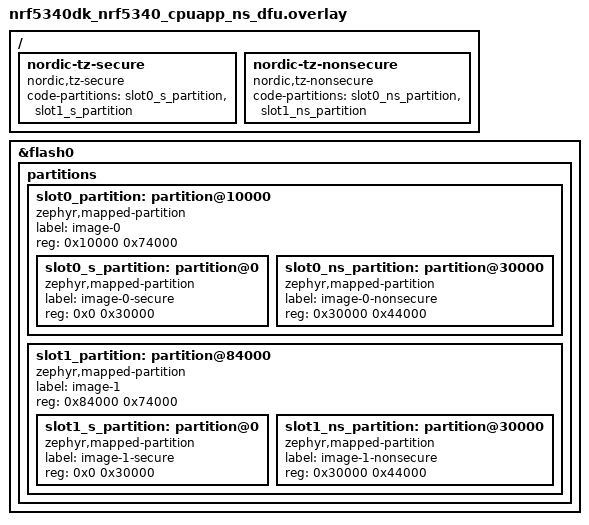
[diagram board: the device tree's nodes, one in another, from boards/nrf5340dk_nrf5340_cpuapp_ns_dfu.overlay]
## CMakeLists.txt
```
#
# Copyright (c) 2019 Nordic Semiconductor ASA
#
# SPDX-License-Identifier: LicenseRef-Nordic-5-Clause
#
cmake_minimum_required(VERSION 3.20.0)

find_package(Zephyr REQUIRED HINTS $ENV{ZEPHYR_BASE})
project(bluetooth_mesh_light)

include_directories(${ZEPHYR_NRF_MODULE_DIR}/samples/bluetooth/mesh/common)

# NORDIC SDK APP START
target_sources(app PRIVATE
  src/main.c
  src/model_handler.c
)
target_include_directories(app PRIVATE
  include
  ${ZEPHYR_NRF_MODULE_DIR}/samples/bluetooth/mesh/common
)

# Preinitialization related to DFU over SMP
target_sources_ifdef(CONFIG_MCUMGR_TRANSPORT_BT app PRIVATE
  ${ZEPHYR_NRF_MODULE_DIR}/samples/bluetooth/mesh/common/smp_bt.c
  ${ZEPHYR_NRF_MODULE_DIR}/samples/bluetooth/mesh/common/mgmt_dfu_hooks.c
)

# NORDIC SDK APP END
```

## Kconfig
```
source "Kconfig.zephyr"

rsource "../common/Kconfig"
```

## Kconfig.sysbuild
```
#
# Copyright (c) 2023 Nordic Semiconductor
#
# SPDX-License-Identifier: LicenseRef-Nordic-5-Clause
#

config NRF_DEFAULT_IPC_RADIO
	default y

config PARTITION_MANAGER
	default n if !BOARD_NRF5340DK_NRF5340_CPUAPP_NS && !BOOTLOADER_MCUBOOT && !BOARD_THINGY53_NRF5340_CPUAPP

source "share/sysbuild/Kconfig"
```

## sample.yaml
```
sample:
  description: Bluetooth Mesh light sample
  name: Bluetooth Mesh light
common:
  tags:
    - bluetooth
    - ci_build
    - sysbuild
    - ci_samples_bluetooth
tests:
  sample.bluetooth.mesh.light:
    sysbuild: true
    build_only: true
    integration_platforms:
      - nrf54l15dk/nrf54l15/cpuapp
    platform_allow:
      - nrf5340dk/nrf5340/cpuapp
      - nrf5340dk/nrf5340/cpuapp/ns
      - nrf54l15dk/nrf54l15/cpuapp
      - nrf54l15dk/nrf54l10/cpuapp
      - nrf54l15dk/nrf54l05/cpuapp
      - nrf54lm20dk/nrf54lm20a/cpuapp
      - nrf54lm20dk/nrf54lm20a/cpuapp/ite
      - nrf54lc10dk/nrf54lc10a/cpuapp
  sample.bluetooth.mesh.light.dfu:
    sysbuild: true
    build_only: true
    integration_platforms:
      - nrf54l15dk/nrf54l15/cpuapp
    platform_allow:
      - nrf5340dk/nrf5340/cpuapp
      - nrf5340dk/nrf5340/cpuapp/ns
      - nrf54l15dk/nrf54l15/cpuapp
      - nrf54l15dk/nrf54l10/cpuapp
      - nrf54lm20dk/nrf54lm20a/cpuapp
      - nrf54lc10dk/nrf54lc10a/cpuapp
    extra_args: FILE_SUFFIX=dfu
  sample.bluetooth.mesh.light.settings_ext_flash:
    sysbuild: true
    build_only: true
    integration_platforms:
      - nrf54l15dk/nrf54l15/cpuapp
    platform_allow:
      - nrf54l15dk/nrf54l15/cpuapp
      - nrf54l15dk/nrf54l10/cpuapp
      - nrf54l15dk/nrf54l05/cpuapp
    extra_args: FILE_SUFFIX=settings_ext_flash
```

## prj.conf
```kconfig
#
# Copyright (c) 2019 Nordic Semiconductor ASA
#
# SPDX-License-Identifier: LicenseRef-Nordic-5-Clause
#
CONFIG_NCS_SAMPLES_DEFAULTS=y

# Deferred logging helps improve LPN power consumption
# when friendship is established.
CONFIG_LOG_MODE_DEFERRED=y

# General configuration
CONFIG_NCS_APPLICATION_BOOT_BANNER_STRING="Mesh Light"
CONFIG_SYSTEM_WORKQUEUE_STACK_SIZE=3072
CONFIG_FLASH=y
CONFIG_FLASH_MAP=y
CONFIG_NVS=y
CONFIG_SETTINGS=y
CONFIG_NVS_LOOKUP_CACHE=y
CONFIG_SETTINGS_NVS_NAME_CACHE=y
CONFIG_HWINFO=y
CONFIG_DK_LIBRARY=y
CONFIG_SOC_FLASH_NRF_PARTIAL_ERASE=y
CONFIG_BT_MESH_NODE_RESET_BUTTON=y

# Bluetooth configuration
CONFIG_BT=y
CONFIG_BT_DEVICE_NAME="Mesh Light"
CONFIG_BT_L2CAP_TX_BUF_COUNT=8

CONFIG_BT_OBSERVER=y
CONFIG_BT_PERIPHERAL=y
CONFIG_BT_SETTINGS=y
# Increase RX stack size to avoid overflow during provisioning
CONFIG_BT_RX_STACK_SIZE=2700

# Disable unused Bluetooth features
CONFIG_BT_CTLR_LE_ENC=n
CONFIG_BT_PHY_UPDATE=n
CONFIG_BT_CTLR_CHAN_SEL_2=n
CONFIG_BT_CTLR_MIN_USED_CHAN=n
CONFIG_BT_CTLR_PRIVACY=n

# Bluetooth Mesh configuration
CONFIG_BT_MESH=y
CONFIG_BT_MESH_RELAY=y
CONFIG_BT_MESH_FRIEND=y
CONFIG_BT_MESH_TX_SEG_MAX=10
CONFIG_BT_MESH_PB_GATT=y
CONFIG_BT_MESH_GATT_PROXY=y
CONFIG_BT_MESH_PROXY_USE_DEVICE_NAME=y
CONFIG_BT_MESH_DK_PROV=y

# Bluetooth Mesh models
CONFIG_BT_MESH_ONOFF_SRV=y

CONFIG_LTO=y
CONFIG_ISR_TABLES_LOCAL_DECLARATION=y
```

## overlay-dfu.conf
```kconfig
#
# Copyright (c) 2022 Nordic Semiconductor ASA
#
# SPDX-License-Identifier: LicenseRef-Nordic-5-Clause
#

# Enable point to point DFU over SMP
CONFIG_BOOTLOADER_MCUBOOT=y
CONFIG_NCS_SAMPLE_MCUMGR_BT_OTA_DFU=y
CONFIG_NCS_SAMPLE_MCUMGR_BT_OTA_DFU_SPEEDUP=y
CONFIG_MCUMGR_TRANSPORT_WORKQUEUE_STACK_SIZE=3072
# Enable Extended Advertiser to advertise BT SMP service
CONFIG_BT_EXT_ADV=y
CONFIG_BT_EXT_ADV_MAX_ADV_SET=6

# One extra connection for mesh GATT/proxy and one for SMP BT.
CONFIG_BT_MAX_CONN=3

# One extra identity for SMP service
CONFIG_BT_ID_MAX=2

# Increase the HCI command buffers to 3 for additional SMP service
CONFIG_BT_BUF_CMD_TX_COUNT=3

# Enable MCUmgr command hooks for doing mesh reset when doing dfu upgrade and storage erase
CONFIG_MCUMGR_MGMT_NOTIFICATION_HOOKS=y
CONFIG_MCUMGR_SMP_COMMAND_STATUS_HOOKS=y
CONFIG_MCUMGR_GRP_OS_RESET_HOOK=y

# Force disconnect after PB-GATT provisioning for proper Proxy transition after DFU
CONFIG_BT_MESH_DK_PROV_PB_GATT_DISCONNECT=y
```

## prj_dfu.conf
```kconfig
#
# Copyright (c) 2026 Nordic Semiconductor ASA
#
# SPDX-License-Identifier: LicenseRef-Nordic-5-Clause
#
CONFIG_NCS_SAMPLES_DEFAULTS=y

# Deferred logging helps improve LPN power consumption
# when friendship is established.
CONFIG_LOG_MODE_DEFERRED=y

# General configuration
CONFIG_NCS_APPLICATION_BOOT_BANNER_STRING="Mesh Light"
CONFIG_SYSTEM_WORKQUEUE_STACK_SIZE=3072
CONFIG_FLASH=y
CONFIG_FLASH_MAP=y
CONFIG_NVS=y
CONFIG_SETTINGS=y
CONFIG_NVS_LOOKUP_CACHE=y
CONFIG_SETTINGS_NVS_NAME_CACHE=y
CONFIG_HWINFO=y
CONFIG_DK_LIBRARY=y
CONFIG_SOC_FLASH_NRF_PARTIAL_ERASE=y

# Bluetooth configuration
CONFIG_BT=y
CONFIG_BT_DEVICE_NAME="Mesh Light"
CONFIG_BT_L2CAP_TX_BUF_COUNT=8

CONFIG_BT_OBSERVER=y
CONFIG_BT_PERIPHERAL=y
CONFIG_BT_SETTINGS=y
# Increase RX stack size to avoid overflow during provisioning
CONFIG_BT_RX_STACK_SIZE=2700

# Disable unused Bluetooth features
CONFIG_BT_CTLR_LE_ENC=n
CONFIG_BT_PHY_UPDATE=n
CONFIG_BT_CTLR_CHAN_SEL_2=n
CONFIG_BT_CTLR_MIN_USED_CHAN=n
CONFIG_BT_CTLR_PRIVACY=n

# Bluetooth Mesh configuration
CONFIG_BT_MESH=y
CONFIG_BT_MESH_RELAY=y
CONFIG_BT_MESH_FRIEND=y
CONFIG_BT_MESH_TX_SEG_MAX=10
CONFIG_BT_MESH_PB_GATT=y
CONFIG_BT_MESH_GATT_PROXY=y
CONFIG_BT_MESH_PROXY_USE_DEVICE_NAME=y
CONFIG_BT_MESH_DK_PROV=y

# Bluetooth Mesh models
CONFIG_BT_MESH_ONOFF_SRV=y

# === BLE DFU configuration ===
# Enable point to point DFU over SMP
CONFIG_BOOTLOADER_MCUBOOT=y
CONFIG_NCS_SAMPLE_MCUMGR_BT_OTA_DFU=y
CONFIG_NCS_SAMPLE_MCUMGR_BT_OTA_DFU_SPEEDUP=y
CONFIG_MCUMGR_TRANSPORT_WORKQUEUE_STACK_SIZE=3072
# Enable Extended Advertiser to advertise BT SMP service
CONFIG_BT_EXT_ADV=y
CONFIG_BT_EXT_ADV_MAX_ADV_SET=6

# One extra connection for mesh GATT/proxy and one for SMP BT.
CONFIG_BT_MAX_CONN=3

# One extra identity for SMP service
CONFIG_BT_ID_MAX=2

# Increase the HCI command buffers to 3 for additional SMP service
CONFIG_BT_BUF_CMD_TX_COUNT=3

# Enable MCUmgr command hooks for doing mesh reset when doing dfu upgrade and storage erase
CONFIG_MCUMGR_MGMT_NOTIFICATION_HOOKS=y
CONFIG_MCUMGR_SMP_COMMAND_STATUS_HOOKS=y
CONFIG_MCUMGR_GRP_OS_RESET_HOOK=y

# Force disconnect after PB-GATT provisioning for proper Proxy transition after DFU
CONFIG_BT_MESH_DK_PROV_PB_GATT_DISCONNECT=y

# Link Time Optimization. CONFIG_LTO depends on ISR_TABLES_LOCAL_DECLARATION
CONFIG_LTO=y
CONFIG_ISR_TABLES_LOCAL_DECLARATION=y
```

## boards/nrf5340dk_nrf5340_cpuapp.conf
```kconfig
#
# Copyright (c) 2024 Nordic Semiconductor ASA
#
# SPDX-License-Identifier: LicenseRef-Nordic-5-Clause
#
################################################################################
# Application overlay - nrf5340dk secure image

CONFIG_SOC_FLASH_NRF_PARTIAL_ERASE=n

# Enable point to point DFU over SMP
CONFIG_BOOTLOADER_MCUBOOT=y
CONFIG_NCS_SAMPLE_MCUMGR_BT_OTA_DFU=y
CONFIG_NCS_SAMPLE_MCUMGR_BT_OTA_DFU_SPEEDUP=y

# Enable updates for the network core
CONFIG_NRF53_UPGRADE_NETWORK_CORE=y
CONFIG_UPDATEABLE_IMAGE_NUMBER=2
CONFIG_MCUBOOT_USE_ALL_AVAILABLE_RAM=y

# Enable Extended Advertiser to advertise BT SMP service
CONFIG_BT_EXT_ADV=y
CONFIG_BT_EXT_ADV_MAX_ADV_SET=6

# One extra connection for mesh GATT/proxy and one for SMP BT.
CONFIG_BT_MAX_CONN=3

# One extra identity for SMP service
CONFIG_BT_ID_MAX=2
```

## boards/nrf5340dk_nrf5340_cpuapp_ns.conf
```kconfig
#
# Copyright (c) 2023 Nordic Semiconductor ASA
#
# SPDX-License-Identifier: LicenseRef-Nordic-5-Clause
#
################################################################################
# Application overlay - nrf5340dk non secure image

CONFIG_SOC_FLASH_NRF_PARTIAL_ERASE=n

# Use the TF-M Profile Small to save ROM and be able to fit when using bootloader
CONFIG_TFM_PROFILE_TYPE_SMALL=y
```

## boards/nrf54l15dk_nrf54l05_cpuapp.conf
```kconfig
#
# Copyright (c) 2024 Nordic Semiconductor ASA
#
# SPDX-License-Identifier: LicenseRef-Nordic-5-Clause
#
################################################################################
# Application overlay - nrf54l05

CONFIG_SOC_FLASH_NRF_PARTIAL_ERASE=n
CONFIG_SPI_NOR=n
CONFIG_NVS=n
CONFIG_NVS_LOOKUP_CACHE=n
CONFIG_SETTINGS_NVS_NAME_CACHE=n
CONFIG_ZMS=y
CONFIG_SETTINGS_ZMS_CUSTOM_SECTOR_COUNT=y
CONFIG_SETTINGS_ZMS_SECTOR_COUNT=8
CONFIG_ZMS_LOOKUP_CACHE=y
CONFIG_ZMS_LOOKUP_CACHE_SIZE=512
CONFIG_ZMS_LOOKUP_CACHE_FOR_SETTINGS=y
CONFIG_SYSTEM_WORKQUEUE_STACK_SIZE=4096
CONFIG_BT_RX_STACK_SIZE=5120
```

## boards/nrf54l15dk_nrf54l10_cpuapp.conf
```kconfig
#
# Copyright (c) 2024 Nordic Semiconductor ASA
#
# SPDX-License-Identifier: LicenseRef-Nordic-5-Clause
#
################################################################################
# Application overlay - nrf54l10

CONFIG_SOC_FLASH_NRF_PARTIAL_ERASE=n
CONFIG_SPI_NOR=n
CONFIG_NVS=n
CONFIG_NVS_LOOKUP_CACHE=n
CONFIG_SETTINGS_NVS_NAME_CACHE=n
CONFIG_ZMS=y
CONFIG_SETTINGS_ZMS_CUSTOM_SECTOR_COUNT=y
CONFIG_SETTINGS_ZMS_SECTOR_COUNT=8
CONFIG_ZMS_LOOKUP_CACHE=y
CONFIG_ZMS_LOOKUP_CACHE_SIZE=512
CONFIG_ZMS_LOOKUP_CACHE_FOR_SETTINGS=y
CONFIG_SYSTEM_WORKQUEUE_STACK_SIZE=4096
CONFIG_BT_RX_STACK_SIZE=5120
```

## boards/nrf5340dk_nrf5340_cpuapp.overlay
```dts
/*
 * Copyright (c) 2024 Nordic Semiconductor ASA
 *
 * SPDX-License-Identifier: LicenseRef-Nordic-5-Clause
 */

/* Enable external flash */
/ {
	chosen {
		nordic,pm-ext-flash = &mx25r64;
	};
};
```

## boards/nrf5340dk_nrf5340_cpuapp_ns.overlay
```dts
/*
 * Copyright (c) 2026 Nordic Semiconductor ASA
 *
 * SPDX-License-Identifier: LicenseRef-Nordic-5-Clause
 */

/* Rebalance secure/non-secure subpartitions to fit larger mesh light NS image.
 * MCUboot is removed; slot0 starts at 0x0 and spans 928 KB (0xe8000).
 * Secure: 128 KB, Non-secure: 800 KB.
 */

/delete-node/ &boot_partition;
/delete-node/ &slot0_partition;

&flash0 {
	partitions {
		slot0_partition: partition@0 {
			compatible = "zephyr,mapped-partition";
			label = "image-0";
			reg = <0x00000000 0xe8000>;
			ranges = <0x0 0x0 0xe8000>;
			#address-cells = <1>;
			#size-cells = <1>;

			slot0_s_partition: partition@0 {
				compatible = "zephyr,mapped-partition";
				label = "image-0-secure";
				reg = <0x00000000 0x20000>;
			};

			slot0_ns_partition: partition@20000 {
				compatible = "zephyr,mapped-partition";
				label = "image-0-nonsecure";
				reg = <0x00020000 0xc8000>;
			};
		};
	};
};

/ {
	/delete-node/ nordic-tz-secure;
	/delete-node/ nordic-tz-nonsecure;

	nordic-tz-secure {
		compatible = "nordic,tz-secure";
		code-partitions = <&slot0_s_partition>;
	};

	nordic-tz-nonsecure {
		compatible = "nordic,tz-nonsecure";
		code-partitions = <&slot0_ns_partition>;
	};
};
```

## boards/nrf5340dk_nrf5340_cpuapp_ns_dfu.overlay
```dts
/*
 * Copyright (c) 2026 Nordic Semiconductor ASA
 *
 * SPDX-License-Identifier: LicenseRef-Nordic-5-Clause
 */

/* Rebalance secure/non-secure subpartitions to fit larger mesh light NS image.
 * Aligned slot0/slot1 addresses and sizes to MCUboot defaults
 * (nrf5340_cpuapp_partition.dtsi): each slot is 0x74000 (464 KB).
 * Secure: 192 KB, Non-secure: 272 KB.
 */

/delete-node/ &slot0_partition;
/delete-node/ &slot1_partition;

&flash0 {
	partitions {
		slot0_partition: partition@10000 {
			compatible = "zephyr,mapped-partition";
			label = "image-0";
			reg = <0x10000 0x74000>;
			ranges = <0x0 0x10000 0x74000>;
			#address-cells = <1>;
			#size-cells = <1>;

			slot0_s_partition: partition@0 {
				compatible = "zephyr,mapped-partition";
				label = "image-0-secure";
				reg = <0x0 0x30000>;
			};

			slot0_ns_partition: partition@30000 {
				compatible = "zephyr,mapped-partition";
				label = "image-0-nonsecure";
				reg = <0x30000 0x44000>;
			};
		};

		slot1_partition: partition@84000 {
			compatible = "zephyr,mapped-partition";
			label = "image-1";
			reg = <0x84000 0x74000>;
			ranges = <0x0 0x84000 0x74000>;
			#address-cells = <1>;
			#size-cells = <1>;

			slot1_s_partition: partition@0 {
				compatible = "zephyr,mapped-partition";
				label = "image-1-secure";
				reg = <0x0 0x30000>;
			};

			slot1_ns_partition: partition@30000 {
				compatible = "zephyr,mapped-partition";
				label = "image-1-nonsecure";
				reg = <0x30000 0x44000>;
			};
		};
	};
};

/ {
	/delete-node/ nordic-tz-secure;
	/delete-node/ nordic-tz-nonsecure;

	nordic-tz-secure {
		compatible = "nordic,tz-secure";
		code-partitions = <&slot0_s_partition>,
				  <&slot1_s_partition>;
	};

	nordic-tz-nonsecure {
		compatible = "nordic,tz-nonsecure";
		code-partitions = <&slot0_ns_partition>,
				  <&slot1_ns_partition>;
	};
};
```

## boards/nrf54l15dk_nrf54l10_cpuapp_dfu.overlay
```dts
/*
 * Copyright (c) 2026 Nordic Semiconductor ASA
 *
 * SPDX-License-Identifier: LicenseRef-Nordic-5-Clause
 */

/delete-node/ &boot_partition;
/delete-node/ &slot0_partition;
/delete-node/ &slot1_partition;
/delete-node/ &storage_partition;

&cpuapp_rram {
	partitions {
		boot_partition: partition@0 {
			label = "mcuboot";
			reg = <0x0 0xe000>;
		};

		slot0_partition: partition@e000 {
			label = "image-0";
			reg = <0xe000 0x73000>;
		};

		slot1_partition: partition@81000 {
			label = "image-1";
			reg = <0x81000 0x73000>;
		};

		storage_partition: partition@f5000 {
			label = "storage";
			reg = <0xf5000 0x8000>;
		};
	};
};
```

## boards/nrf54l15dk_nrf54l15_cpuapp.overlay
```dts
/*
 * Copyright (c) 2026 Nordic Semiconductor ASA
 *
 * SPDX-License-Identifier: LicenseRef-Nordic-5-Clause
 */

/delete-node/ &boot_partition;
/delete-node/ &slot0_partition;
/delete-node/ &slot1_partition;
/delete-node/ &storage_partition;

&cpuapp_rram {
	partitions {
		boot_partition: partition@0 {
			label = "mcuboot";
			reg = <0x0 0xe000>;
		};

		slot0_partition: partition@e000 {
			label = "image-0";
			reg = <0xe000 0xa7000>;
		};

		slot1_partition: partition@b5000 {
			label = "image-1";
			reg = <0xb5000 0xa7000>;
		};

		storage_partition: partition@15d000 {
			label = "storage";
			reg = <0x15d000 0x8000>;
		};
	};
};
```

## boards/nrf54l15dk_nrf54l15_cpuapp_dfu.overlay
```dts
/*
 * Copyright (c) 2026 Nordic Semiconductor ASA
 *
 * SPDX-License-Identifier: LicenseRef-Nordic-5-Clause
 */

/delete-node/ &boot_partition;
/delete-node/ &slot0_partition;
/delete-node/ &slot1_partition;
/delete-node/ &storage_partition;

&cpuapp_rram {
	partitions {
		boot_partition: partition@0 {
			compatible = "zephyr,mapped-partition";
			label = "mcuboot";
			reg = <0x0 0xe000>;
		};

		slot0_partition: partition@e000 {
			compatible = "zephyr,mapped-partition";
			label = "image-0";
			reg = <0xe000 0xa7000>;
		};

		slot1_partition: partition@b5000 {
			compatible = "zephyr,mapped-partition";
			label = "image-1";
			reg = <0xb5000 0xa7000>;
		};

		storage_partition: partition@15d000 {
			compatible = "zephyr,mapped-partition";
			label = "storage";
			reg = <0x15d000 0x8000>;
		};
	};
};
```

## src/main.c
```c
/*
 * Copyright (c) 2019 Nordic Semiconductor ASA
 *
 * SPDX-License-Identifier: LicenseRef-Nordic-5-Clause
 */

/** @file
 *  @brief Nordic mesh light sample
 */
#include <zephyr/bluetooth/bluetooth.h>
#include <bluetooth/mesh/models.h>
#include <bluetooth/mesh/dk_prov.h>
#include <dk_buttons_and_leds.h>
#include <bluetooth/mesh/node_reset_button.h>
#include "model_handler.h"
#include "smp_bt.h"

static void bt_ready(int err)
{
	if (err) {
		printk("Bluetooth init failed (err %d)\n", err);
		return;
	}

	printk("Bluetooth initialized\n");

	err = dk_leds_init();
	if (err) {
		printk("Initializing LEDs failed (err %d)\n", err);
		return;
	}

	err = dk_buttons_init(NULL);
	if (err) {
		printk("Initializing buttons failed (err %d)\n", err);
		return;
	}

	if (IS_ENABLED(CONFIG_BT_MESH_NODE_RESET_BUTTON)) {
		bt_mesh_node_reset_button_init();
	}

	err = bt_mesh_init(bt_mesh_dk_prov_init(), model_handler_init());
	if (err) {
		printk("Initializing mesh failed (err %d)\n", err);
		return;
	}

	if (IS_ENABLED(CONFIG_SETTINGS)) {
		settings_load();
	}

	/* This will be a no-op if settings_load() loaded provisioning info */
	bt_mesh_prov_enable(BT_MESH_PROV_ADV | BT_MESH_PROV_GATT);

	printk("Mesh initialized\n");

	if (IS_ENABLED(CONFIG_MCUMGR_TRANSPORT_BT)) {
		err = smp_dfu_init();
		if (err) {
			printk("Unable to initialize DFU (err %d)\n", err);
		}
	}
}

int main(void)
{
	int err;

	printk("Initializing...\n");

	err = bt_enable(bt_ready);
	if (err) {
		printk("Bluetooth init failed (err %d)\n", err);
	}

	return 0;
}
```

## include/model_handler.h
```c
/*
 * Copyright (c) 2019 Nordic Semiconductor ASA
 *
 * SPDX-License-Identifier: LicenseRef-Nordic-5-Clause
 */

/**
 * @file
 * @brief Model handler
 */

#ifndef MODEL_HANDLER_H__
#define MODEL_HANDLER_H__

#include <zephyr/bluetooth/mesh.h>

#ifdef __cplusplus
extern "C" {
#endif

const struct bt_mesh_comp *model_handler_init(void);

#ifdef __cplusplus
}
#endif

#endif /* MODEL_HANDLER_H__ */
```

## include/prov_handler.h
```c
/*
 * Copyright (c) 2019 Nordic Semiconductor ASA
 *
 * SPDX-License-Identifier: LicenseRef-BSD-5-Clause-Nordic
 */

/**
 * @file
 * @brief Provisioning handler
 */

#ifndef PROV_HANDLER_H__
#define PROV_HANDLER_H__

#include <bluetooth/mesh.h>

#ifdef __cplusplus
extern "C" {
#endif

const struct bt_mesh_prov *prov_handler_init(void);

#ifdef __cplusplus
}
#endif

#endif /* PROV_HANDLER_H__ */
```

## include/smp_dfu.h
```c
/*
 * Copyright (c) 2022 Nordic Semiconductor ASA
 *
 * SPDX-License-Identifier: LicenseRef-Nordic-5-Clause
 */

/**
 * @file
 * @brief SMP DFU support
 */

#ifndef SMP_DFU_H__
#define SMP_DFU_H__

#ifdef __cplusplus
extern "C" {
#endif

int smp_dfu_init(void);

#ifdef __cplusplus
}
#endif

#endif /* SMP_DFU_H__ */
```

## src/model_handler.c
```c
/*
 * Copyright (c) 2019 Nordic Semiconductor ASA
 *
 * SPDX-License-Identifier: LicenseRef-Nordic-5-Clause
 */

#include <zephyr/bluetooth/bluetooth.h>
#include <bluetooth/mesh/models.h>
#include <dk_buttons_and_leds.h>
#include "model_handler.h"

static void led_set(struct bt_mesh_onoff_srv *srv, struct bt_mesh_msg_ctx *ctx,
		    const struct bt_mesh_onoff_set *set,
		    struct bt_mesh_onoff_status *rsp);

static void led_get(struct bt_mesh_onoff_srv *srv, struct bt_mesh_msg_ctx *ctx,
		    struct bt_mesh_onoff_status *rsp);

static const struct bt_mesh_onoff_srv_handlers onoff_handlers = {
	.set = led_set,
	.get = led_get,
};

struct led_ctx {
	struct bt_mesh_onoff_srv srv;
	struct k_work_delayable work;
	uint32_t remaining;
	bool value;
};

static struct led_ctx led_ctx[] = {
#if DT_NODE_EXISTS(DT_ALIAS(led0))
	{ .srv = BT_MESH_ONOFF_SRV_INIT(&onoff_handlers) },
#endif
#if DT_NODE_EXISTS(DT_ALIAS(led1))
	{ .srv = BT_MESH_ONOFF_SRV_INIT(&onoff_handlers) },
#endif
#if DT_NODE_EXISTS(DT_ALIAS(led2))
	{ .srv = BT_MESH_ONOFF_SRV_INIT(&onoff_handlers) },
#endif
#if DT_NODE_EXISTS(DT_ALIAS(led3))
	{ .srv = BT_MESH_ONOFF_SRV_INIT(&onoff_handlers) },
#endif
};

static void led_transition_start(struct led_ctx *led)
{
	int led_idx = led - &led_ctx[0];

	/* As long as the transition is in progress, the onoff
	 * state is "on":
	 */
	dk_set_led(led_idx, true);
	k_work_reschedule(&led->work, K_MSEC(led->remaining));
	led->remaining = 0;
}

static void led_status(struct led_ctx *led, struct bt_mesh_onoff_status *status)
{
	/* Do not include delay in the remaining time. */
	status->remaining_time = led->remaining ? led->remaining :
		k_ticks_to_ms_ceil32(k_work_delayable_remaining_get(&led->work));
	status->target_on_off = led->value;
	/* As long as the transition is in progress, the onoff state is "on": */
	status->present_on_off = led->value || status->remaining_time;
}

static void led_set(struct bt_mesh_onoff_srv *srv, struct bt_mesh_msg_ctx *ctx,
		    const struct bt_mesh_onoff_set *set,
		    struct bt_mesh_onoff_status *rsp)
{
	struct led_ctx *led = CONTAINER_OF(srv, struct led_ctx, srv);
	int led_idx = led - &led_ctx[0];

	if (set->on_off == led->value) {
		goto respond;
	}

	led->value = set->on_off;
	if (!bt_mesh_model_transition_time(set->transition)) {
		led->remaining = 0;
		dk_set_led(led_idx, set->on_off);
		goto respond;
	}

	led->remaining = set->transition->time;

	if (set->transition->delay) {
		k_work_reschedule(&led->work, K_MSEC(set->transition->delay));
	} else {
		led_transition_start(led);
	}

respond:
	if (rsp) {
		led_status(led, rsp);
	}
}

static void led_get(struct bt_mesh_onoff_srv *srv, struct bt_mesh_msg_ctx *ctx,
		    struct bt_mesh_onoff_status *rsp)
{
	struct led_ctx *led = CONTAINER_OF(srv, struct led_ctx, srv);

	led_status(led, rsp);
}

static void led_work(struct k_work *work)
{
	struct led_ctx *led = CONTAINER_OF(work, struct led_ctx, work.work);
	int led_idx = led - &led_ctx[0];

	if (led->remaining) {
		led_transition_start(led);
	} else {
		dk_set_led(led_idx, led->value);

		/* Publish the new value at the end of the transition */
		struct bt_mesh_onoff_status status;

		led_status(led, &status);
		bt_mesh_onoff_srv_pub(&led->srv, NULL, &status);
	}
}

/* Set up a repeating delayed work to blink the DK's LEDs when attention is
 * requested.
 */
static struct k_work_delayable attention_blink_work;
static bool attention;

static void attention_blink(struct k_work *work)
{
	static int idx;
	const uint8_t pattern[] = {
#if DT_NODE_EXISTS(DT_ALIAS(led0))
		BIT(0),
#endif
#if DT_NODE_EXISTS(DT_ALIAS(led1))
		BIT(1),
#endif
#if DT_NODE_EXISTS(DT_ALIAS(led2))
		BIT(2),
#endif
#if DT_NODE_EXISTS(DT_ALIAS(led3))
		BIT(3),
#endif
	};

	if (attention) {
		dk_set_leds(pattern[idx++ % ARRAY_SIZE(pattern)]);
		k_work_reschedule(&attention_blink_work, K_MSEC(30));
	} else {
		dk_set_leds(DK_NO_LEDS_MSK);
	}
}

static void attention_on(const struct bt_mesh_model *mod)
{
	attention = true;
	k_work_reschedule(&attention_blink_work, K_NO_WAIT);
}

static void attention_off(const struct bt_mesh_model *mod)
{
	/* Will stop rescheduling blink timer */
	attention = false;
}

static const struct bt_mesh_health_srv_cb health_srv_cb = {
	.attn_on = attention_on,
	.attn_off = attention_off,
};

static struct bt_mesh_health_srv health_srv = {
	.cb = &health_srv_cb,
};

BT_MESH_HEALTH_PUB_DEFINE(health_pub, 0);

static struct bt_mesh_elem elements[] = {
#if DT_NODE_EXISTS(DT_ALIAS(led0))
	BT_MESH_ELEM(
		1, BT_MESH_MODEL_LIST(
			BT_MESH_MODEL_CFG_SRV,
			BT_MESH_MODEL_HEALTH_SRV(&health_srv, &health_pub),
			BT_MESH_MODEL_ONOFF_SRV(&led_ctx[0].srv)),
		BT_MESH_MODEL_NONE),
#endif
#if DT_NODE_EXISTS(DT_ALIAS(led1))
	BT_MESH_ELEM(
		2, BT_MESH_MODEL_LIST(BT_MESH_MODEL_ONOFF_SRV(&led_ctx[1].srv)),
		BT_MESH_MODEL_NONE),
#endif
#if DT_NODE_EXISTS(DT_ALIAS(led2))
	BT_MESH_ELEM(
		3, BT_MESH_MODEL_LIST(BT_MESH_MODEL_ONOFF_SRV(&led_ctx[2].srv)),
		BT_MESH_MODEL_NONE),
#endif
#if DT_NODE_EXISTS(DT_ALIAS(led3))
	BT_MESH_ELEM(
		4, BT_MESH_MODEL_LIST(BT_MESH_MODEL_ONOFF_SRV(&led_ctx[3].srv)),
		BT_MESH_MODEL_NONE),
#endif
};

static const struct bt_mesh_comp comp = {
	.cid = CONFIG_BT_COMPANY_ID,
	.elem = elements,
	.elem_count = ARRAY_SIZE(elements),
};

const struct bt_mesh_comp *model_handler_init(void)
{
	k_work_init_delayable(&attention_blink_work, attention_blink);

	for (int i = 0; i < ARRAY_SIZE(led_ctx); ++i) {
		k_work_init_delayable(&led_ctx[i].work, led_work);
	}

	return &comp;
}
```

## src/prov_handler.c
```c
/*
 * Copyright (c) 2019 Nordic Semiconductor ASA
 *
 * SPDX-License-Identifier: LicenseRef-BSD-5-Clause-Nordic
 */

#include <bluetooth/mesh.h>
#include <dk_buttons_and_leds.h>
#include <drivers/hwinfo.h>

static u32_t oob_toggles;
static u32_t oob_toggle_count;
static struct k_delayed_work oob_work;
static u32_t button_press_count;

static void oob_blink_toggle(struct k_work *work)
{
	dk_set_leds(((oob_toggle_count++) & 0x01) ? DK_NO_LEDS_MSK :
						    DK_ALL_LEDS_MSK);
	if (oob_toggle_count == oob_toggles) {
		oob_toggle_count = 0;
		k_delayed_work_submit(
			CONTAINER_OF(work, struct k_delayed_work, work), 3000);
	} else {
		k_delayed_work_submit(
			CONTAINER_OF(work, struct k_delayed_work, work), 250);
	}
}

static int output_number(bt_mesh_output_action_t action, u32_t number)
{
	if (action == BT_MESH_DISPLAY_NUMBER) {
		printk("OOB Number: %u\n", number);
	} else if (action == BT_MESH_BLINK) {
		printk("Blinking %u times\n", number);
		oob_toggles = number * 2;
		oob_toggle_count = 0;
		k_delayed_work_init(&oob_work, oob_blink_toggle);
		k_delayed_work_submit(&oob_work, 0);
	}
	return 0;
}


static void oob_button_timeout(struct k_work *work)
{
	dk_buttons_init(NULL);
	dk_set_leds(DK_NO_LEDS_MSK);

	bt_mesh_input_number(button_press_count);
}

static void oob_button_handler(u32_t button_state, u32_t has_changed)
{
	if (button_state & has_changed) {
		button_press_count++;
		dk_set_leds((1 << button_press_count) - 1);
		k_delayed_work_submit(&oob_work, 3000);
	}
}

static int input(bt_mesh_input_action_t act, u8_t size)
{
	printk("Press a button to set the right number.\n");
	k_delayed_work_init(&oob_work, oob_button_timeout);
	dk_buttons_init(oob_button_handler);
	button_press_count = true;
	return true;
}

static void input_complete(void)
{
	k_delayed_work_cancel(&oob_work);
}

static void prov_complete(u16_t net_idx, u16_t src)
{
	k_delayed_work_cancel(&oob_work);
	dk_buttons_init(NULL);
	printk("Prov complete! Addr: 0x%04x\n", src);
}

static void prov_reset(void)
{
	k_delayed_work_cancel(&oob_work);
	dk_buttons_init(NULL);
	bt_mesh_prov_enable(BT_MESH_PROV_ADV | BT_MESH_PROV_GATT);
}

static u8_t dev_uuid[16];

static const struct bt_mesh_prov prov = {
	.uuid = dev_uuid,
	.output_size = 1,
	.output_actions = BT_MESH_DISPLAY_NUMBER | BT_MESH_BLINK,
	.output_number = output_number,
	.input_size = 1,
	.input = input,
	.input_actions = BT_MESH_PUSH,
	.complete = prov_complete,
	.input_complete = input_complete,
	.reset = prov_reset,
};

const struct bt_mesh_prov *prov_handler_init(void)
{
	hwinfo_get_device_id(dev_uuid, sizeof(dev_uuid));
	return &prov;
}
```

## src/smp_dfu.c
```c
/*
 * Copyright (c) 2022 Nordic Semiconductor ASA
 *
 * SPDX-License-Identifier: LicenseRef-Nordic-5-Clause
 */

#include <zephyr/init.h>

/* .. include_startingpoint_light_smp_dfu_rst_1 */
#include <zephyr/bluetooth/bluetooth.h>
#include <zephyr/bluetooth/conn.h>

static void pending_adv_start(struct k_work *work);

static struct bt_le_ext_adv *adv;
/* This will result in the device advertising SMP service continuously. If this is undesirable,
 * set timeout to a finite value, and then create a mechanism in the application (e.g. by pressing
 * a button) to start SMP advertisements when needed by calling @ref bt_le_ext_adv_start.
 */
static struct bt_le_ext_adv_start_param ext_adv_param = { .num_events = 0, .timeout = 0 };
static struct k_work_delayable adv_work = Z_WORK_DELAYABLE_INITIALIZER(pending_adv_start);

static struct bt_le_adv_param adv_params = {
	.id = BT_ID_DEFAULT,
	.sid = 0,
	.secondary_max_skip = 0,
	.options = BT_LE_ADV_OPT_CONNECTABLE | BT_LE_ADV_OPT_USE_NAME,
	.interval_min = BT_GAP_ADV_SLOW_INT_MIN,
	.interval_max = BT_GAP_ADV_SLOW_INT_MAX,
	.peer = NULL
};

static const struct bt_data ad[] = {
	BT_DATA_BYTES(BT_DATA_FLAGS, (BT_LE_AD_GENERAL | BT_LE_AD_NO_BREDR)),
	BT_DATA_BYTES(BT_DATA_UUID128_ALL, 0x84, 0xaa, 0x60, 0x74, 0x52, 0x8a, 0x8b, 0x86, 0xd3,
		      0x4c, 0xb7, 0x1d, 0x1d, 0xdc, 0x53, 0x8d),
};

static void pending_adv_start(struct k_work *work)
{
	int err;

	err = bt_le_ext_adv_start(adv, &ext_adv_param);
	if (err) {
		printk("Unable to restart SMP service advertising (err %d)\n", err);
		return;
	}

	printk("SMP service advertising restarted\n");
}

static void connected(struct bt_conn *conn, uint8_t err)
{
	struct bt_conn_info cinfo;
	int ec;

	ec = bt_conn_get_info(conn, &cinfo);
	if (ec) {
		printk("Unable to get connection info (err %d)\n", ec);
		return;
	}

	if (cinfo.id != adv_params.id) {
		return;
	}

	printk("Connected to SMP service: err %d id %d\n", err, cinfo.id);
}

static void disconnected(struct bt_conn *conn, uint8_t reason)
{
	int err;
	struct bt_conn_info cinfo;

	err = bt_conn_get_info(conn, &cinfo);
	if (err) {
		printk("Unable to get connection info (err %d)\n", err);
		return;
	}

	if (cinfo.id != adv_params.id) {
		return;
	}

	printk("Disconnected from SMP service: reason %d id %d\n", reason, cinfo.id);

	k_work_schedule(&adv_work, K_NO_WAIT);
}

static struct bt_conn_cb conn_callbacks = {
	.connected = connected,
	.disconnected = disconnected,
};

int smp_service_adv_init(void)
{
	int err;
	size_t id_count = 0xFF;
	int id;

	/* Use different identity from Bluetooth mesh to avoid conflicts with Mesh Provisioning
	 * Service and Mesh Proxy Service advertisements.
	 */
	bt_id_get(NULL, &id_count);

	if (id_count < CONFIG_BT_ID_MAX) {
		id = bt_id_create(NULL, NULL);
		if (id < 0) {
			printk("Unable to create a new identity for SMP (err %d)."
			       " Using the default one.\n", id);
			id = BT_ID_DEFAULT;
		}

		printk("Created a new identity for SMP: %d\n", id);
	} else {
		id = BT_ID_DEFAULT + 1;
		printk("Recovered identity for SMP: %d\n", id);
	}

	adv_params.id = id;

	err = bt_le_ext_adv_create(&adv_params, NULL, &adv);
	if (err) {
		printk("Creating SMP service adv instance failed (err %d)\n", err);
		return err;
	}

	err = bt_le_ext_adv_set_data(adv, ad, ARRAY_SIZE(ad), NULL, 0);
	if (err) {
		printk("Setting SMP service adv data failed (err %d)\n", err);
		return err;
	}

	err = bt_le_ext_adv_start(adv, &ext_adv_param);
	if (err) {
		printk("Starting advertising of SMP service failed (err %d)\n", err);
	}

	return err;
}
/* .. include_endpoint_light_smp_dfu_rst_1 */

int smp_dfu_init(void)
{
/* .. include_startingpoint_light_smp_dfu_rst_2 */
	bt_conn_cb_register(&conn_callbacks);

	/**
	 * Since Bluetooth mesh utilizes the advertiser as the main channel of
	 * communication, a secondary advertising set is necessary to broadcast
	 * the SMP service.
	 */
	return smp_service_adv_init();
/* .. include_endpoint_light_smp_dfu_rst_2 */
}
```
